# RL6845_IP_SVD register map
Vendor: Realtek
Registers are 32-bit, read-write, reset 0x0 unless marked. A register's access mark holds for its fields unless they carry their own. Offsets are from the block's base; [hi:lo] are bit positions; {n}, {i} and the like mark numbered series; <NAME> marks a mode.

## page5
Base 0x40000000
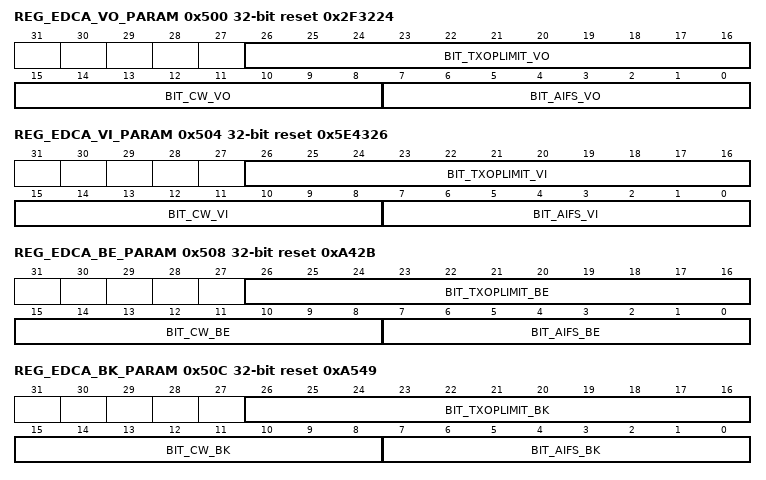
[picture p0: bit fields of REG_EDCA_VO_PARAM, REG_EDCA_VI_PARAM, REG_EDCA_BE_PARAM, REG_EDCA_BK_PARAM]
0x500 REG_EDCA_VO_PARAM reset 0x2F3224
  [26:16] BIT_TXOPLIMIT_VO — TXOP Limit An unsigned integer in units of 32 microseconds. Value of zero indicates that a single MSDU or MMPDU in addition to a protection frame exchange can be transmitted at any rate. Default: BK = 0h; BE = 0h; VI = 5Eh; VO = 2Fh.
  [15:8] BIT_CW_VO — ECWmin and ECWmax encode the values of Cwmin and Cwmax respectively in an exponent form. Ex: Cwmax = 2^(ECWmax)-1 Default: BK = Ah/5h; BE = Ah/5h; VI = 5h/4h; VO = 4h/3h.
  [7:0] BIT_AIFS_VO — Arbitrary Inter frame space In unit of microsecond. AIFS indicates the time a non-AP QSTA should defer before either invoking a backoff or starting a transmission Default: BK = 49h; BE = 25h; VI = 1Ch; VO = 1Ch.
0x504 REG_EDCA_VI_PARAM reset 0x5E4326
  [26:16] BIT_TXOPLIMIT_VI — TXOP Limit An unsigned integer in units of 32 microseconds. Value of zero indicates that a single MSDU or MMPDU in addition to a protection frame exchange can be transmitted at any rate. Default: BK = 0h; BE = 0h; VI = 5Eh; VO = 2Fh.
  [15:8] BIT_CW_VI — ECWmin and ECWmax encode the values of Cwmin and Cwmax respectively in an exponent form. Ex: Cwmax = 2^(ECWmax)-1 Default: BK = Ah/5h; BE = Ah/5h; VI = 5h/4h; VO = 4h/3h.
  [7:0] BIT_AIFS_VI — Arbitrary Inter frame space In unit of microsecond. AIFS indicates the time a non-AP QSTA should defer before either invoking a backoff or starting a transmission Default: BK = 49h; BE = 25h; VI = 1Ch; VO = 1Ch.
0x508 REG_EDCA_BE_PARAM reset 0xA42B
  [26:16] BIT_TXOPLIMIT_BE — TXOP Limit An unsigned integer in units of 32 microseconds. Value of zero indicates that a single MSDU or MMPDU in addition to a protection frame exchange can be transmitted at any rate. Default: BK = 0h; BE = 0h; VI = 5Eh; VO = 2Fh.
  [15:8] BIT_CW_BE — ECWmin and ECWmax encode the values of Cwmin and Cwmax respectively in an exponent form. Ex: Cwmax = 2^(ECWmax)-1 Default: BK = Ah/5h; BE = Ah/5h; VI = 5h/4h; VO = 4h/3h.
  [7:0] BIT_AIFS_BE — Arbitrary Inter frame space In unit of microsecond. AIFS indicates the time a non-AP QSTA should defer before either invoking a backoff or starting a transmission Default: BK = 49h; BE = 25h; VI = 1Ch; VO = 1Ch.
0x50C REG_EDCA_BK_PARAM reset 0xA549
  [26:16] BIT_TXOPLIMIT_BK — TXOP Limit An unsigned integer in units of 32 microseconds. Value of zero indicates that a single MSDU or MMPDU in addition to a protection frame exchange can be transmitted at any rate. Default: BK = 0h; BE = 0h; VI = 5Eh; VO = 2Fh.
  [15:8] BIT_CW_BK — ECWmin and ECWmax encode the values of Cwmin and Cwmax respectively in an exponent form. Ex: Cwmax = 2^(ECWmax)-1 Default: BK = Ah/5h; BE = Ah/5h; VI = 5h/4h; VO = 4h/3h.
  [7:0] BIT_AIFS_BK — Arbitrary Inter frame space In unit of microsecond. AIFS indicates the time a non-AP QSTA should defer before either invoking a backoff or starting a transmission Default: BK = 49h; BE = 25h; VI = 1Ch; VO = 1Ch.
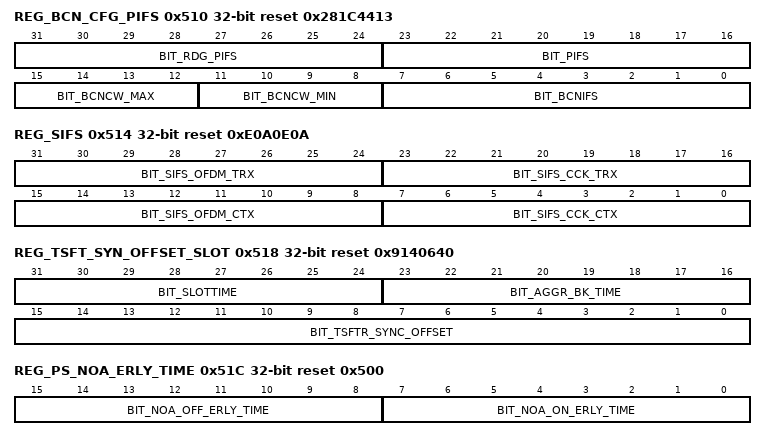
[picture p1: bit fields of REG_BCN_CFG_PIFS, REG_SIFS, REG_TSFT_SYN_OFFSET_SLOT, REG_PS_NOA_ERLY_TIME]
0x510 REG_BCN_CFG_PIFS reset 0x281C4413
  [31:24] BIT_RDG_PIFS — PIFS time. It is only used in RDG mode and in units of us.
  [23:16] BIT_PIFS — PIFS time. It is only used in AP mode and in units of us.
  [15:12] BIT_BCNCW_MAX — Beacon Contention Window MAX Defines the contention window value for back off before transmitting beacon frame. This field is set to 0 in AP mode to indicate no back off window. In ad hoc mode, its default value is 6. 26-1 = 63 time slots.
  [11:8] BIT_BCNCW_MIN — Beacon Contention Window Defines the contention window value for back off before transmitting beacon frame. This field is set to 0 in AP mode to indicate no back off window. In ad hoc mode, its default value is 6. 26-1 = 63 time slots.
  [7:0] BIT_BCNIFS — Beacon Interframe Space In units of microseconds, this register defines the medium idle time required before transmitting beacon (AP mode) or entering random back off window.
0x514 REG_SIFS reset 0xE0A0E0A
  [31:24] BIT_SIFS_OFDM_TRX — This register sets the SIFS time required in NAV protection period after receiving any immediate response. for example Ack-Data or RTS/CTS-Data. It is in unit of us.
  [23:16] BIT_SIFS_CCK_TRX — This register sets the SIFS time required in NAV protection period after receiving any immediate response. for example Ack-Data or RTS/CTS-Data. It is in unit of us.
  [15:8] BIT_SIFS_OFDM_CTX — This register sets the SIFS time required for consecutive TX events for example CTS2S-Data, or broadcast bursting. It is in unit of us.
  [7:0] BIT_SIFS_CCK_CTX — This register sets the SIFS time required for consecutive TX events for example CTS2S-Data, or broadcast bursting. It is in unit of us.
0x518 REG_TSFT_SYN_OFFSET_SLOT reset 0x9140640
  [31:24] BIT_SLOTTIME — This register sets the slot time value mentioned in 802.11 specification. It is in units of us. Default: 0x9
  [23:16] BIT_AGGR_BK_TIME — Hw will break aggr. In sifs condition
  [15:0] BIT_TSFTR_SYNC_OFFSET — tsft sync. Offset (bcn0 sync to bcn1 offset or bcn1 sync to bcn0 offset). Unit : 32us, default is 50ms
0x51C REG_PS_NOA_ERLY_TIME reset 0x500
  [15:8] BIT_NOA_OFF_ERLY_TIME — NOA off early interval, Time unit is TU.
  [7:0] BIT_NOA_ON_ERLY_TIME — not valid. NOA on early interval, Time unit is TU. PS: This function has some issue, so it's value must be 0
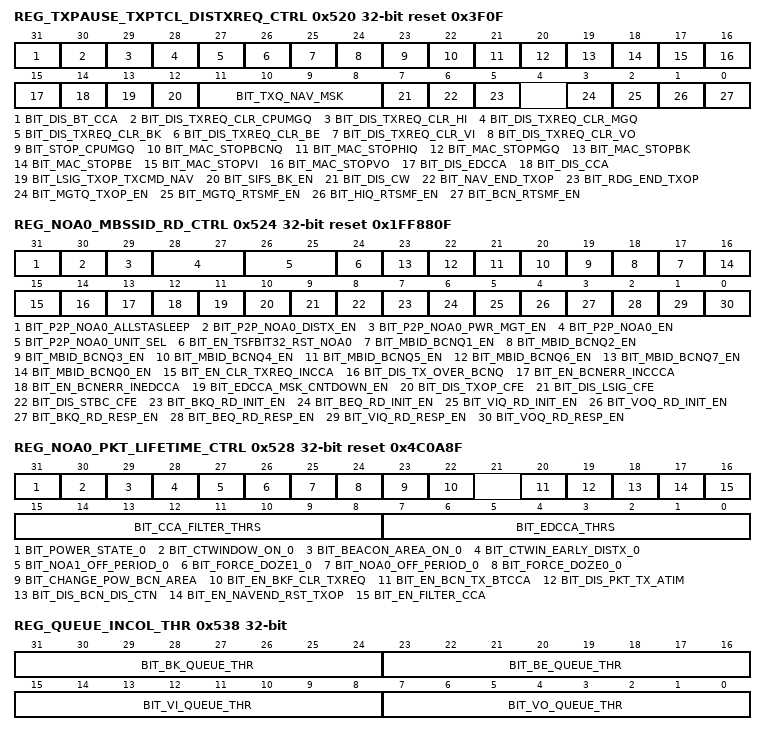
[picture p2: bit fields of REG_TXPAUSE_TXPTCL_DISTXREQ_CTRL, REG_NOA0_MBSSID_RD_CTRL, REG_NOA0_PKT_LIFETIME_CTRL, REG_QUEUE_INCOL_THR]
0x520 REG_TXPAUSE_TXPTCL_DISTXREQ_CTRL reset 0x3F0F
  [31] BIT_DIS_BT_CCA — Disable BT_CCA.
  [30] BIT_DIS_TXREQ_CLR_CPUMGQ — 1: if this queue can't own channel ,txcmd will be cleared 0:Only TX_finish can clear txreq
  [29] BIT_DIS_TXREQ_CLR_HI — 0: if this queue can't own channel ,txcmd will be cleared 1:Only TX_finish can clear txreq
  [28] BIT_DIS_TXREQ_CLR_MGQ — 1: if this queue can't own channel ,txcmd will be cleared 0:Only TX_finish can clear txreq
  [27] BIT_DIS_TXREQ_CLR_BK — 0: if this queue can't own channel ,txcmd will be cleared 1:Only TX_finish can clear txreq
  [26] BIT_DIS_TXREQ_CLR_BE — 0: if this queue can't own channel ,txcmd will be cleared 1:Only TX_finish can clear txreq
  [25] BIT_DIS_TXREQ_CLR_VI — 0: if this queue can't own channel ,txcmd will be cleared 1:Only TX_finish can clear txreq
  [24] BIT_DIS_TXREQ_CLR_VO — 0: if this queue can't own channel ,txcmd will be cleared 1:Only TX_finish can clear txreq
  [23] BIT_STOP_CPUMGQ — To control CPUMGQ queues contention circuit. 1: CPUMGQ queues all stop. 0: Enable CPUMGQ queues contention circuit
  [22] BIT_MAC_STOPBCNQ — Stop BCNQ Queue Write a 1 to this bit via software to immediately stop the transmission of packet from this queue including retry attempts.
  [21] BIT_MAC_STOPHIQ — Stop High Queue Write a 1 to this bit via software to immediately stop the transmission of packet from this queue including retry attempts.
  [20] BIT_MAC_STOPMGQ — Stop Management Queue Write a 1 to this bit via software to immediately stop the transmission of packet from this queue including retry attempts.
  [19] BIT_MAC_STOPBK — Stop BK Queue Write a 1 to this bit via software to immediately stop the transmission of packet from this queue including retry attempts.
  [18] BIT_MAC_STOPBE — Stop BE Queue Write a 1 to this bit via software to immediately stop the transmission of packet from this queue including retry attempts.
  [17] BIT_MAC_STOPVI — Stop VI Queue Write a 1 to this bit via software to immediately stop the transmission of packet from this queue including retry attempts.
  [16] BIT_MAC_STOPVO — Stop VO Queue Write a 1 to this bit via software to immediately stop the transmission of packet from this queue including retry attempts.
  [15] BIT_DIS_EDCCA — Disable EDCCA function. 0: PHY_EDCCA can block TX (default) 1: PHY_EDCCA cannot block TX OK -> TX beacon; X -> cannot TX beacon 0x528[7] 0x520[15] 0x520[14] TX bcn TX bcn (OFDMCCA=0, (OFDMCCA=1, EDCCA=1) EDCCA=1) 0 0 0 X X 0 0 1 X X 0 1 0 OK X 0 1 1 OK OK 1 0 0 X X 1 0 1 X X 1 1 0 OK X 1 1 1 OK OK
  [14] BIT_DIS_CCA — Disable CCA.
  [13] BIT_LSIG_TXOP_TXCMD_NAV — Set LSIG_TXOP from TXCMD_NAV field
  [12] BIT_SIFS_BK_EN — SIFS Break Check Criteria enable for AMPDU aggregation
  [11:8] BIT_TXQ_NAV_MSK — 1: Queue BKF must wait TX Nav finished 0: Queue not need wait
  [7] BIT_DIS_CW — When this bit is set, disable CW.
  [6] BIT_NAV_END_TXOP — 1: In txop mode, Nav protect all txop 0: In txop mode, Nav protect to next pkt
  [5] BIT_RDG_END_TXOP — 1: In tx RDG mode, Nav protect all txop 0: In tx RDG mode, Nav protect to next pkt
  [3] BIT_MGTQ_TXOP_EN — When this bit is set, MGTQ may sent packets by using ACQ TXOP.
  [2] BIT_MGTQ_RTSMF_EN — When this bit is set, MTGQ will be TX, not wait until RTS or MF transaction finished.
  [1] BIT_HIQ_RTSMF_EN — When this bit is set, HIQ will be TX, not wait until RTS or MF transaction finished.
  [0] BIT_BCN_RTSMF_EN — When this bit is set, BCNQ will be TX, not wait until RTS or MF transaction finished.
0x524 REG_NOA0_MBSSID_RD_CTRL reset 0x1FF880F
  [31] BIT_P2P_NOA0_ALLSTASLEEP — It indicates that the state from CTWindow End to BcnEarly 1: Sleep 0: Wake
  [30] BIT_P2P_NOA0_DISTX_EN — 1: Hw will disable TX in P2P_off period 0: Do Nothing
  [29] BIT_P2P_NOA0_PWR_MGT_EN — A main switch for P2P PowerSaving 1: Enable 0: Disable
  [28:27] BIT_P2P_NOA0_EN — The condition that noa_unit0, [1]-NOA1, [0]-NOA0 1: Enable 0: Disable
  [26:25] BIT_P2P_NOA0_UNIT_SEL — The selector for the source of noa unit0. 0 for port 0, 1 for port 1,2 for port2
  [24] BIT_EN_TSFBIT32_RST_NOA0 — when enable, if tsft_bit32_int is asserted, reset power_cs of noa_unit0
  [n+16] BIT_MBID_BCNQ{n}_EN (n=1..7) — When enable, auto MBSSID for virtual interface {n} is enable.
  [16] BIT_MBID_BCNQ0_EN — When enable, auto MBSSID for root interface is enable.
  [15] BIT_EN_CLR_TXREQ_INCCA — not valid.
  [14] BIT_DIS_TX_OVER_BCNQ — 1: Tx Packet with ignoring Beacon Area time 0: Disable
  [13] BIT_EN_BCNERR_INCCCA — eneble force tx becon ignore CCA in disable contention area
  [12] BIT_EN_BCNERR_INEDCCA — eneble force tx becon ignore EDCCA in disable contention area
  [11] BIT_EDCCA_MSK_CNTDOWN_EN — 1: disable EDCCA count down, 0: enable EDCCA count down AC backoff 是否需要參考PHY_EDCCA 0: 不參考PHY_EDCCA 1: 參考PHY_EDCCA (default, PHY_EDCCA=1時停止backoff)
  [10] BIT_DIS_TXOP_CFE — Disable TXOP_CFE function
  [9] BIT_DIS_LSIG_CFE — Disable LSIG_TXOP CF-END function
  [8] BIT_DIS_STBC_CFE — Disable STBC CF-END function
  [7] BIT_BKQ_RD_INIT_EN — Enable BKQ RD initiator function
  [6] BIT_BEQ_RD_INIT_EN — Enable BEQ RD initiator function
  [5] BIT_VIQ_RD_INIT_EN — Enable VIQ RD initiator function
  [4] BIT_VOQ_RD_INIT_EN — Enable VOQ RD initiator function
  [3] BIT_BKQ_RD_RESP_EN — Enable BKQ RD responder function
  [2] BIT_BEQ_RD_RESP_EN — Enable BEQ RD responder function
  [1] BIT_VIQ_RD_RESP_EN — Enable VIQ RD responder function
  [0] BIT_VOQ_RD_RESP_EN — Enable VOQ RD responder function
0x528 REG_NOA0_PKT_LIFETIME_CTRL access per field reset 0x4C0A8F
  [31] BIT_POWER_STATE_0 ro — 1: On, 0: Off. (It is including early time. )
  [30] BIT_CTWINDOW_ON_0 ro — Spec time and Beacon Early Time to TBTT Time. (It is including early time. )
  [29] BIT_BEACON_AREA_ON_0 ro — The time is from HOLD Time to BeaconTx or Timeout. (It is including early time. )
  [28] BIT_CTWIN_EARLY_DISTX_0 ro — ctwin_early_distx. (It is including early time. )
  [27] BIT_NOA1_OFF_PERIOD_0 ro — Spec time but exclude BCNDMATIM time for wake. (It is including early time. )
  [26] BIT_FORCE_DOZE1_0 ro — If NoA_Count == 1, this value is 1. else 0. (It is including early time. )
  [25] BIT_NOA0_OFF_PERIOD_0 ro — Spec time but exclude BCNDMATIM time for wake. (It is including early time. )
  [24] BIT_FORCE_DOZE0_0 ro — If NoA_Count == 1, this value is 1. else 0. (It is including early time. )
  [23] BIT_CHANGE_POW_BCN_AREA rw — select real_ctwindow & real_bcnq_area for noa_unit
  [22] BIT_EN_BKF_CLR_TXREQ rw — when gen tx command done, while will backoff is invalid, then tx command will be cleared
  [20] BIT_EN_BCN_TX_BTCCA rw — 1: Enable Beacon Tx at TBTT if BT_CCA is enabled 0: Disable
  [19] BIT_DIS_PKT_TX_ATIM rw — 1: Disable AC Queue Packet Tx in ATIM (only valid at Nettype: Adhoc/AP) 0: Enable AC Queue packet Tx in ATIM
  [18] BIT_DIS_BCN_DIS_CTN rw — Disable the Beacon queue disable contention,when set to 0 enable the force beacon function.
  [17] BIT_EN_NAVEND_RST_TXOP rw — When set this bit, TXOP will be reset while NAV end.
  [16] BIT_EN_FILTER_CCA rw — Enable CCA filter threshold
  [15:8] BIT_CCA_FILTER_THRS rw — If PHY_CCA signal width is bigger than this threshold, this PHY_CCA signal is valid for MAC. Unit: us
  [7:0] BIT_EDCCA_THRS rw — EDCCA threshold value, edcca over this threshold will cause bkf_rst Bit[7]: PHY_EDCCA為1時,當timer timeout時擋住TX Bit[6:0]: timer (單位:32us)
0x530 REG_P2PON_DIS_TXTIME
  [15:8] BIT_P2PON_DIS_TXTIME — The time of the disable TX period after the P2P RF on interrupt occur. Unit: 64us.
0x534 REG_NAN_SETTING_2 reset 0x168
  [13:0] BIT_SYNC_BCN_DELAY — r_HC * r_SLOTTIME * 8'd40 (unit:us) default: r_HC = 1, r_SLOTTIME = 9, => 360us max is 16ms (DW)
0x538 REG_QUEUE_INCOL_THR
  [31:24] BIT_BK_QUEUE_THR — 0: Disable this BK queue condition. Otherwise: When internal collision number of queue equal threshold, the priority of queue enhance. But have more 2 queues which satisfy each queue threshold, the priority will follow VO>VI>BE>BK.
  [23:16] BIT_BE_QUEUE_THR — 0: Disable this BE queue condition. Otherwise: When internal collision number of queue equal threshold, the priority of queue enhance. But have more 2 queues which satisfy each queue threshold, the priority will follow VO>VI>BE>BK.
  [15:8] BIT_VI_QUEUE_THR — 0: Disable this VI queue condition. Otherwise: When internal collision number of queue equal threshold, the priority of queue enhance. But have more 2 queues which satisfy each queue threshold, the priority will follow VO>VI>BE>BK.
  [7:0] BIT_VO_QUEUE_THR — 0: Disable this VO queue condition. Otherwise: When internal collision number of queue equal threshold, the priority of queue enhance. But have more 2 queues which satisfy each queue threshold, the priority will follow VO>VI>BE>BK.
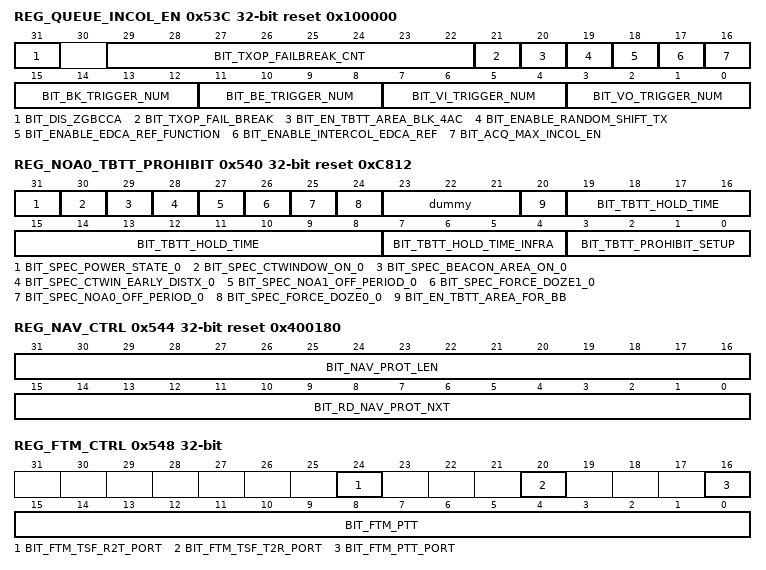
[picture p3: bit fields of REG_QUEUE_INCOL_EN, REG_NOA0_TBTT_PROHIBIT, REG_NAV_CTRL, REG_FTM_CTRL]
0x53C REG_QUEUE_INCOL_EN access per field reset 0x100000
  [31] BIT_DIS_ZGBCCA rw — Disable zigbee CCA
  [29:22] BIT_TXOP_FAILBREAK_CNT ro — if BIT_TXOP_FAIL_BREAK = 1, counter the times of txfail break TXOP
  [21] BIT_TXOP_FAIL_BREAK rw — 1: if tx pkt fail in txop, then tx cfend to end txop
  [20] BIT_EN_TBTT_AREA_BLK_4AC rw — When set this bit, 4AC backoff is disabled on TBTT setup period
  [19] BIT_ENABLE_RANDOM_SHIFT_TX rw — When this bit set 1, enable random shift TX function
  [18] BIT_ENABLE_EDCA_REF_FUNCTION rw — When this bit set 1, enable EDCA REF function
  [17] BIT_ENABLE_INTERCOL_EDCA_REF rw — When this bit set 1, enable inter-collision edca_ref
  [16] BIT_ACQ_MAX_INCOL_EN rw — 1:Enable 0 :Disable
  [15:12] BIT_BK_TRIGGER_NUM ro — The number is triggered by bkq inter collision
  [11:8] BIT_BE_TRIGGER_NUM ro — The number is triggered by beq inter collision
  [7:4] BIT_VI_TRIGGER_NUM ro — The number is triggered by viq inter collision
  [3:0] BIT_VO_TRIGGER_NUM ro — The number is triggered by voq inter collision
0x540 REG_NOA0_TBTT_PROHIBIT access per field reset 0xC812
  [31] BIT_SPEC_POWER_STATE_0 ro — 1: On, 0: Off
  [30] BIT_SPEC_CTWINDOW_ON_0 ro — The time from TBTT <-> CTWEND (with BCNDMATIM early time)
  [29] BIT_SPEC_BEACON_AREA_ON_0 ro — The time is from TBTT to BeaconTx or Timeout
  [28] BIT_SPEC_CTWIN_EARLY_DISTX_0 ro — ctwin_early_distx
  [27] BIT_SPEC_NOA1_OFF_PERIOD_0 ro — Spec time
  [26] BIT_SPEC_FORCE_DOZE1_0 ro — If NoA_Count == 1, this value is 1. else 0.
  [25] BIT_SPEC_NOA0_OFF_PERIOD_0 ro — Spec time
  [24] BIT_SPEC_FORCE_DOZE0_0 ro — If NoA_Count == 1, this value is 1. else 0.
  [23:21] dummy rw
  [20] BIT_EN_TBTT_AREA_FOR_BB rw — enable notify bb that mac p0 is in tbtt area
  [19:8] BIT_TBTT_HOLD_TIME rw — TBTT_prohibit_hold time for AP mode, unit is 32 us
  [7:4] BIT_TBTT_HOLD_TIME_INFRA rw — TBTT_prohibit_hold time for infrastructure mode , unit is 2 ms
  [3:0] BIT_TBTT_PROHIBIT_SETUP rw — TBTT_prohibit_setup, unit is 32us
0x544 REG_NAV_CTRL reset 0x400180
  [31:16] BIT_NAV_PROT_LEN — In TXOP mode ,NAV setting which protects next packets
  [15:0] BIT_RD_NAV_PROT_NXT — In RDG mode ,NAV setting which protects next packets
0x548 REG_FTM_CTRL
  [24] BIT_FTM_TSF_R2T_PORT — 0:R2T latch count sync tsf of port 0 1: R2T latch count sync tsf of port 1
  [20] BIT_FTM_TSF_T2R_PORT — 0:T2R latch count sync tsf of port 0 1: T2R latch count sync tsf of port 1
  [16] BIT_FTM_PTT_PORT — 0: sync tsf of port 0 1: sync tsf of port 1
  [15:0] BIT_FTM_PTT — partial tsf timer setting
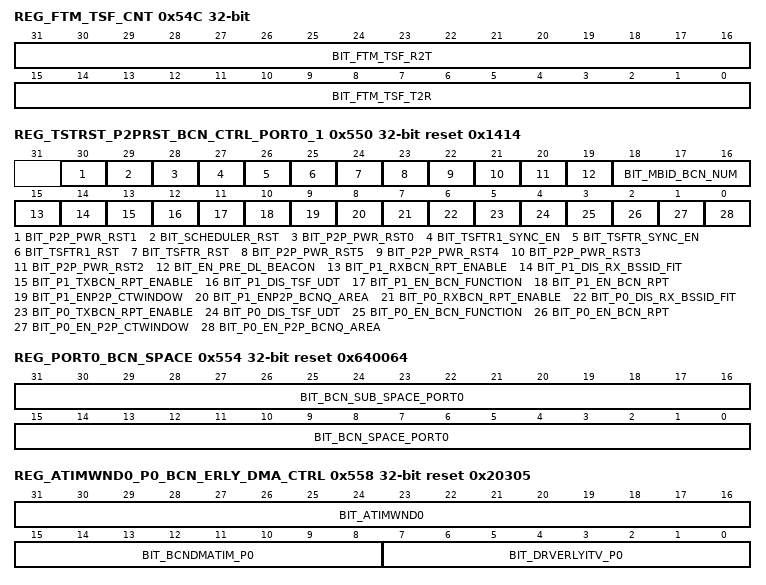
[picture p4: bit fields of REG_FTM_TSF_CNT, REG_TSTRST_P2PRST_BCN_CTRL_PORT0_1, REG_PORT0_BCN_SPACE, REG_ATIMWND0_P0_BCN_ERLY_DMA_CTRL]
0x54C REG_FTM_TSF_CNT ro
  [31:16] BIT_FTM_TSF_R2T — R2T latch count sync tsf timer
  [15:0] BIT_FTM_TSF_T2R — T2R latch count sync tsf timer
0x550 REG_TSTRST_P2PRST_BCN_CTRL_PORT0_1 access per field reset 0x1414
  [30] BIT_P2P_PWR_RST1 wo — rst p2p circuit NOA 1, noa_unit0
  [29] BIT_SCHEDULER_RST wo — Write this bit reset scheduler, ioreg_txfail
  [28] BIT_P2P_PWR_RST0 wo — rst p2p circuit NOA 0, noa_unit0
  [27] BIT_TSFTR1_SYNC_EN wo — write this bit, bcn1 will sync to bcn0 with TSFTF_SYN_OFFSET
  [26] BIT_TSFTR_SYNC_EN wo — write this bit, bcn0 will sync to bcn1 with TSFTF_SYN_OFFSET
  [25] BIT_TSFTR1_RST wo — write this bit , bcn1 tsft will auto reset
  [24] BIT_TSFTR_RST wo — write this bit , bcn0 tsft will auto reset
  [23] BIT_P2P_PWR_RST5 wo — rst p2p circuit NOA 5, noa_unit2
  [22] BIT_P2P_PWR_RST4 wo — rst p2p circuit NOA 4, noa_unit2
  [21] BIT_P2P_PWR_RST3 wo — rst p2p circuit NOA 3, noa_unit1
  [20] BIT_P2P_PWR_RST2 wo — rst p2p circuit NOA 2, noa_unit1
  [19] BIT_EN_PRE_DL_BEACON rw — If set 1, hw will enable pre_download beacon
  [18:16] BIT_MBID_BCN_NUM rw — The number of virtual interface number excluding the root number.
  [15] BIT_P1_RXBCN_RPT_ENABLE rw — When this bit asserted, RXBCNOK report is issued
  [14] BIT_P1_DIS_RX_BSSID_FIT rw — 0:HW will handle rx_beacon 1:HW will ignore rx_beacon_pk
  [13] BIT_P1_TXBCN_RPT_ENABLE rw — When this bit and BIT_P1_EN_BCN_RPT are set, then TXBCN ERROR report is issued
  [12] BIT_P1_DIS_TSF_UDT rw — When set, disable clint 0 TSF update when beacon frames or probe response frames are received.
  [11] BIT_P1_EN_BCN_FUNCTION rw — When this bit is set, TSF and other beacon related functions are then enabled. 0x700(MACID1)的enable開關
  [10] BIT_P1_EN_BCN_RPT rw — When this bit asserted, txbcnok_int and txbcnerr_int will valid.
  [9] BIT_P1_ENP2P_CTWINDOW rw — 1: Enable P2P CTN WINDOWS function. 0: Disable P2P CTN WINDOWS function.
  [8] BIT_P1_ENP2P_BCNQ_AREA rw — 1: Enable P2P BCN area on function. 0 : Disable P2P BCN area on function.
  [7] BIT_P0_RXBCN_RPT_ENABLE rw — When this bit asserted, RXBCNOK report is issued
  [6] BIT_P0_DIS_RX_BSSID_FIT rw — 0:HW will handle rx_beacon 1:HW will ignore rx_beacon_pk
  [5] BIT_P0_TXBCN_RPT_ENABLE rw — When this bit and BIT_P0_EN_BCN_RPT are set, then TXBCN ERROR report is issued
  [4] BIT_P0_DIS_TSF_UDT rw — When set, disable port 0 TSF update when beacon frames or probe response frames are received.
  [3] BIT_P0_EN_BCN_FUNCTION rw — When this bit is set, TSF and other beacon related functions are then enabled. 0x610(MACID)的enable開關
  [2] BIT_P0_EN_BCN_RPT rw — When this bit asserted, txbcnok_int and txbcnerr_int will valid.
  [1] BIT_P0_EN_P2P_CTWINDOW rw — 1: Enable P2P CTN WINDOWS function. 0: Disable P2P CTN WINDOWS function.
  [0] BIT_P0_EN_P2P_BCNQ_AREA rw — 1: Enable P2P BCN area on function. 0 : Disable P2P BCN area on function.
0x554 REG_PORT0_BCN_SPACE reset 0x640064
  [31:16] BIT_BCN_SUB_SPACE_PORT0 — Unit is ms. The sub-beacon interval of the port 0.(valid if mbssid function is enable)
  [15:0] BIT_BCN_SPACE_PORT0 — Unit is ms. When MBSSID is disable, this field is the beacon interval. When MBSSID is enable, this register is the beacon space of root.
0x558 REG_ATIMWND0_P0_BCN_ERLY_DMA_CTRL reset 0x20305
  [31:16] BIT_ATIMWND0 — ATIM window width of root VAP in units of TU.
  [15:8] BIT_BCNDMATIM_P0 — Indicates the time before TBTT to perform beacon queue DMA. This register is shared by the time to assert ATIM window end interrupt. Measured in units of "TU" before TBTT and before ATIM window end.
  [7:0] BIT_DRVERLYITV_P0 — Time to send interrupt to notify driver to change beacon content. Time unit is TU. The register also is shared by P2P-CTW and P2P-NoA (from NoA-Absent to NoA-On). It is used to wake up early at DriverEarlyTime
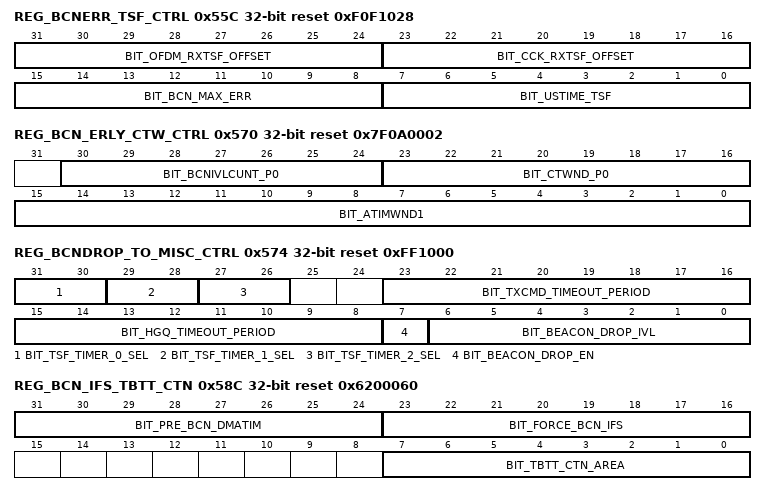
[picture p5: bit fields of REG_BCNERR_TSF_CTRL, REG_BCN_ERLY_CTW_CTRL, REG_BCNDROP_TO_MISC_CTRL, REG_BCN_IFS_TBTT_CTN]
0x55C REG_BCNERR_TSF_CTRL reset 0xF0F1028
  [31:24] BIT_OFDM_RXTSF_OFFSET — The Datapath of OFDM RX_tsf
  [23:16] BIT_CCK_RXTSF_OFFSET — The Datapath of CCK RX_tsf
  [15:8] BIT_BCN_MAX_ERR — When beacon TX error counter goes over this threshold, Beacon will transmit within PIFS.
  [7:0] BIT_USTIME_TSF — Set the microsecond time unit used by MAC TSF clock. 0x14 - 20MHz 0x28 - 40MHz 0x50 - 80MHz
0x560 REG_P0_TSFTR_L reset 0x1
  [31:0] BIT_P0_TSF_TIMER_L — low 32bits of port0's tsft
0x564 REG_P0_TSFTR_H
  [31:0] BIT_P0_TSF_TIMER_H — high 32bits of port0's tsft
0x568 REG_P1_TSFTR_L reset 0x1
  [31:0] BIT_P1_TSF_TIMER_L — low 32bits of port1's tsft
0x56C REG_P1_TSFTR_H reset 0x1
  [31:0] BIT_P1_TSF_TIMER_H — high 32bits of port1's tsft
0x570 REG_BCN_ERLY_CTW_CTRL access per field reset 0x7F0A0002
  [30:24] BIT_BCNIVLCUNT_P0 ro — Be used in multiple BCNIVL early INT. When this counter =1, multiple BCNIVL early INT will be triggered.
  [23:16] BIT_CTWND_P0 rw — CTWindow width in units of TU. PORT0
  [15:0] BIT_ATIMWND1 rw — ATIM window width of VAP1 in units of TU.
0x574 REG_BCNDROP_TO_MISC_CTRL reset 0xFF1000
  [31:30] BIT_TSF_TIMER_0_SEL — genarete tsfime_int[0] 00: PORT0's tsft 01: PORT1's tsft 10:PORT2's tsft 11: FREERUN CUT
  [29:28] BIT_TSF_TIMER_1_SEL — genarete tsfime_int[1] 00: PORT0's tsft 01: PORT1's tsft 10:PORT2's tsft 11: FREERUN CUT
  [27:26] BIT_TSF_TIMER_2_SEL — genarete tsfime_int[2] 00: PORT0's tsft 01: PORT1's tsft 10:PORT2's tsft 11: FREERUN CUT
  [23:16] BIT_TXCMD_TIMEOUT_PERIOD — When 40M/80M TX CMD ready and secondary_CCA_20/secondary_CCA_40 set for this period, then the TX CMD will be cleared. TU: 1us
  [15:8] BIT_HGQ_TIMEOUT_PERIOD — When hgq empty for this period, close atim window. And this will block hgq dma for pcie, unless 0x524[12] set enable. TU: 32us
  [7] BIT_BEACON_DROP_EN — enable beacon drop function
  [6:0] BIT_BEACON_DROP_IVL — indicate the timeout of beacon drop
0x578 REG_P2_TSFTR_L reset 0x1
  [31:0] BIT_P2_TSF_TIMER_L — low 32bits of port2's tsft
0x57C REG_P2_TSFTR_H reset 0x1
  [31:0] BIT_P2_TSF_TIMER_H — high 32bits of port2's tsft
{0x57C+4i} REG_TSF_TIMER{i} (i=1..3)
  [31:5] BIT_TSTTIMER{i} — When the lower 4 bytes of TSFTR matches the content of this register, the FW tsftime_int[{i-1}] interrupt is issued.
0x58C REG_BCN_IFS_TBTT_CTN reset 0x6200060
  [31:24] BIT_PRE_BCN_DMATIM — when 0x552[3] is set, hw will enable pre_download beacon. this register Indicates the time before TBTT to perform beacon queue DMA.
  [23:16] BIT_FORCE_BCN_IFS — when 0x528 Bit18 set to 0 and TBTT contention area end,force tx beacon use this IFS
  [7:0] BIT_TBTT_CTN_AREA — TBTT contention area,Time unit is 32us,for PORT 0 / 1 / 2
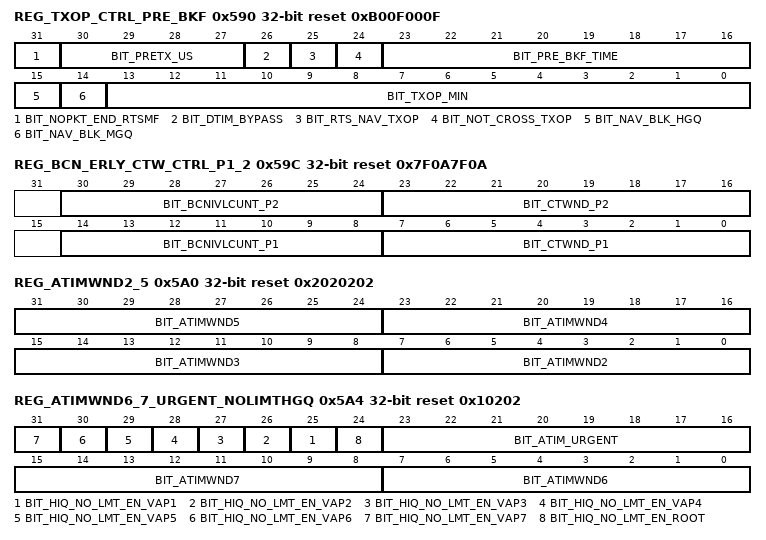
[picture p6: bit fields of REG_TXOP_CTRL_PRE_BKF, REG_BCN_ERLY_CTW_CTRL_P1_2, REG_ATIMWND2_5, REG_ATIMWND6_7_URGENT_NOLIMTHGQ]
0x590 REG_TXOP_CTRL_PRE_BKF reset 0xB00F000F
  [31] BIT_NOPKT_END_RTSMF — 1: enable exit rts hold mode when there is no corresponding ac pkt to tx
  [30:27] BIT_PRETX_US — For wep/tkip, enable security engine earlier than mactx by this amount of time. Unit is microsecond (us)
  [26] BIT_DTIM_BYPASS — 1: dtim counter will keep 0
  [25] BIT_RTS_NAV_TXOP — enable RTS NAV protect all txop
  [24] BIT_NOT_CROSS_TXOP — 1:tx pkt cross tbtt is prohibited 0:tx pkt cross tbtt is permitted
  [23:16] BIT_PRE_BKF_TIME — when bkf timer count down this value, sel queue and gen txcmd will start
  [15] BIT_NAV_BLK_HGQ — rxnav block HGQ
  [14] BIT_NAV_BLK_MGQ — rxnav block MGQ
  [13:0] BIT_TXOP_MIN — if txop counter is more than this value, than tx pkt is considered not cross tbtt
0x594 REG_FREERUN_CNT_L reset 0x1
  [31:0] BIT_FREERUN_CNT_TIMER_L — LOW 32bits of freerun cnt
0x598 REG_FREERUN_CNT_H reset 0x1
  [31:0] BIT_FREERUN_CNT_TIMER_H — high 32bits of freerun cnt
0x59C REG_BCN_ERLY_CTW_CTRL_P1_2 access per field reset 0x7F0A7F0A
  [30:24] BIT_BCNIVLCUNT_P2 ro — Be used in multiple BCNIVL early INT. When this counter =1, multiple BCNIVL early INT will be triggered.
  [23:16] BIT_CTWND_P2 rw — CTWindow width in units of TU. PORT2
  [14:8] BIT_BCNIVLCUNT_P1 ro — Be used in multiple BCNIVL early INT. When this counter =1, multiple BCNIVL early INT will be triggered.
  [7:0] BIT_CTWND_P1 rw — CTWindow width in units of TU. PORT1
0x5A0 REG_ATIMWND2_5 reset 0x2020202
  [8n-9:8n-16] BIT_ATIMWND{n} (n=2..5) — ATIM window width of VAP{n} in units of TU.
0x5A4 REG_ATIMWND6_7_URGENT_NOLIMTHGQ reset 0x10202
  [n+24] BIT_HIQ_NO_LMT_EN_VAP{n} (n=1..7) — 1: Packet in Hi Queue Tx immediately (No constraint for ATIM Period) 0: Disable
  [24] BIT_HIQ_NO_LMT_EN_ROOT — 1: Packet in Hi Queue Tx immediately (No constraint for ATIM Period) 0: Disable
  [23:16] BIT_ATIM_URGENT — Indicates the time before ATIM Window end . When BSSID[n] (n=0~7) has HIQ packet to send, HW only DMA BSSID[n]'s HIQ packet in this interval. (unit : TU)
  [15:8] BIT_ATIMWND7 — ATIM window width of VAP7 in units of TU.
  [7:0] BIT_ATIMWND6 — ATIM window width of VAP6 in units of TU.
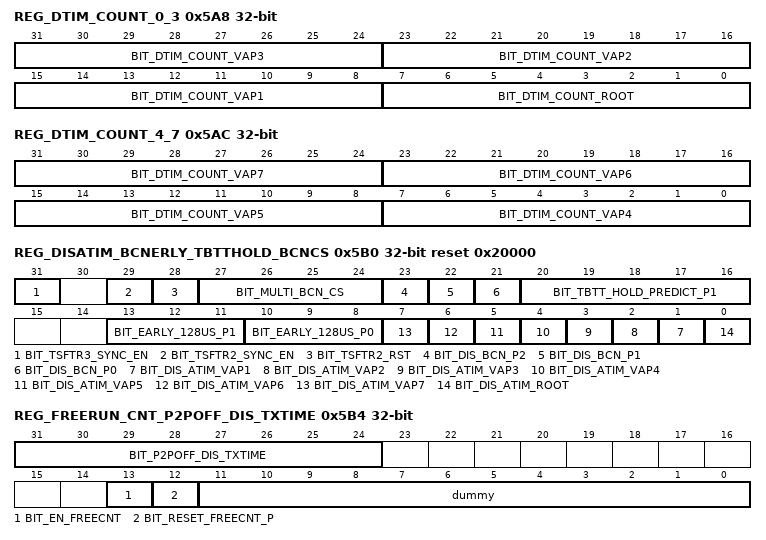
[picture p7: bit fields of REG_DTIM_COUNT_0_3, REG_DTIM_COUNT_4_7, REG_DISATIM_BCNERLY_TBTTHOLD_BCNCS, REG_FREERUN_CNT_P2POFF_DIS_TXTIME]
0x5A8 REG_DTIM_COUNT_0_3
  [31:24] BIT_DTIM_COUNT_VAP3, [23:16] BIT_DTIM_COUNT_VAP2, [15:8] BIT_DTIM_COUNT_VAP1, [7:0] BIT_DTIM_COUNT_ROOT
0x5AC REG_DTIM_COUNT_4_7
  [8n-25:8n-32] BIT_DTIM_COUNT_VAP{n} (n=4..7)
0x5B0 REG_DISATIM_BCNERLY_TBTTHOLD_BCNCS access per field reset 0x20000
  [31] BIT_TSFTR3_SYNC_EN wo — write this bit, PORT3 will sync to PORT2 with TSFTF_SYN_OFFSET
  [29] BIT_TSFTR2_SYNC_EN wo — write this bit, PORT2 will sync to PORT3 with TSFTF_SYN_OFFSET
  [28] BIT_TSFTR2_RST wo — write this bit , bcn2 tsft will auto reset
  [27:24] BIT_MULTI_BCN_CS ro — indicate which port is tx beacon
  [23] BIT_DIS_BCN_P2 rw — set 1 to mask the beacon early interrupt of port2
  [22] BIT_DIS_BCN_P1 rw — set 1 to mask the beacon early interrupt of port1
  [21] BIT_DIS_BCN_P0 rw — set 1 to mask the beacon early interrupt of port0
  [20:16] BIT_TBTT_HOLD_PREDICT_P1 rw — the predicted hold time after tbtt for beacon tx of port1, unit is 32us
  [13:11] BIT_EARLY_128US_P1 rw — the BCN EARLY interrupt find tune with unit 128us. The Total Early time of BCN early interrupt is the 0x558 x 1ms + EARLY_128us x 128us. For port 1
  [10:8] BIT_EARLY_128US_P0 rw — the BCN EARLY interrupt find tune with unit 128us. The Total Early time of BCN early interrupt is the 0x558 x 1ms + EARLY_128us x 128us.
  [n] BIT_DIS_ATIM_VAP{n} rw (n=1..7)
  [0] BIT_DIS_ATIM_ROOT rw
0x5B4 REG_FREERUN_CNT_P2POFF_DIS_TXTIME access per field
  [31:24] BIT_P2POFF_DIS_TXTIME rw — The time of the disable TX period after the P2P RF off interrupt occur. Unit: 64us.
  [13] BIT_EN_FREECNT rw — enable freerun tsft
  [12] BIT_RESET_FREECNT_P wo — reset pulse of freerun tsft
  [11:0] dummy rw
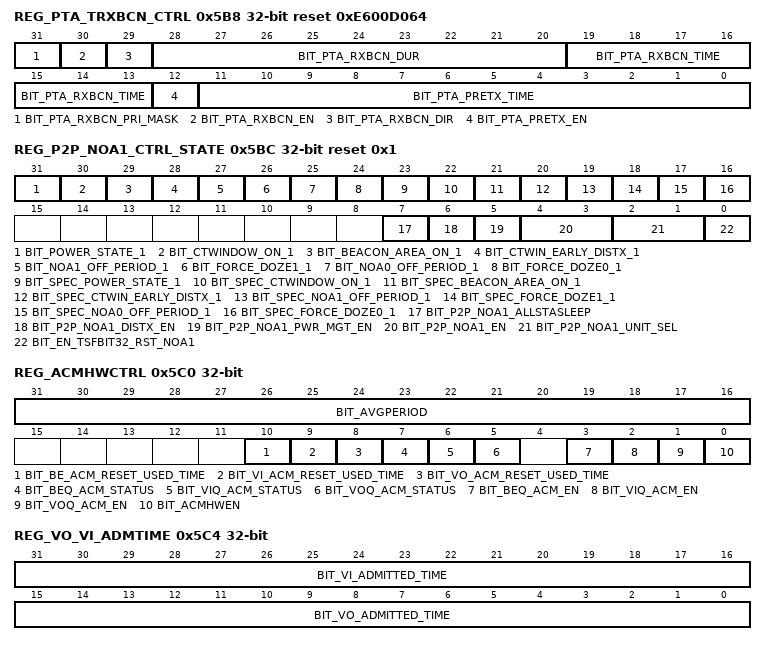
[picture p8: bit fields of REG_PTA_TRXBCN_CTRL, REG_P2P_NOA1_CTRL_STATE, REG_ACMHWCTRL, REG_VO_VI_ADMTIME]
0x5B8 REG_PTA_TRXBCN_CTRL reset 0xE600D064
  [31] BIT_PTA_RXBCN_PRI_MASK
  [30] BIT_PTA_RXBCN_EN
  [29] BIT_PTA_RXBCN_DIR
  [28:20] BIT_PTA_RXBCN_DUR
  [19:13] BIT_PTA_RXBCN_TIME
  [12] BIT_PTA_PRETX_EN
  [11:0] BIT_PTA_PRETX_TIME — WIFI TX shall wait settle time when antenna is switched from BT to WIFI, if the BT use the same RFAFE as WIFI. Unit: 1us
0x5BC REG_P2P_NOA1_CTRL_STATE access per field reset 0x1
  [31] BIT_POWER_STATE_1 ro — 1: On, 0: Off. (It is including early time. )
  [30] BIT_CTWINDOW_ON_1 ro — Spec time and Beacon Early Time to TBTT Time. (It is including early time. )
  [29] BIT_BEACON_AREA_ON_1 ro — The time is from HOLD Time to BeaconTx or Timeout. (It is including early time. )
  [28] BIT_CTWIN_EARLY_DISTX_1 ro — ctwin_early_distx. (It is including early time. )
  [27] BIT_NOA1_OFF_PERIOD_1 ro — Spec time but exclude BCNDMATIM time for wake. (It is including early time. )
  [26] BIT_FORCE_DOZE1_1 ro — If NoA_Count == 1, this value is 1. else 0. (It is including early time. )
  [25] BIT_NOA0_OFF_PERIOD_1 ro — Spec time but exclude BCNDMATIM time for wake. (It is including early time. )
  [24] BIT_FORCE_DOZE0_1 ro — If NoA_Count == 1, this value is 1. else 0. (It is including early time. )
  [23] BIT_SPEC_POWER_STATE_1 ro — 1: On, 0: Off
  [22] BIT_SPEC_CTWINDOW_ON_1 ro — The time from TBTT <-> CTWEND (with BCNDMATIM early time)
  [21] BIT_SPEC_BEACON_AREA_ON_1 ro — The time is from TBTT to BeaconTx or Timeout
  [20] BIT_SPEC_CTWIN_EARLY_DISTX_1 ro — ctwin_early_distx
  [19] BIT_SPEC_NOA1_OFF_PERIOD_1 ro — Spec time
  [18] BIT_SPEC_FORCE_DOZE1_1 ro — If NoA_Count == 1, this value is 1. else 0.
  [17] BIT_SPEC_NOA0_OFF_PERIOD_1 ro — Spec time
  [16] BIT_SPEC_FORCE_DOZE0_1 ro — If NoA_Count == 1, this value is 1. else 0.
  [7] BIT_P2P_NOA1_ALLSTASLEEP rw — It indicates that the state from CTWindow End to BcnEarly 1: Sleep 0: Wake
  [6] BIT_P2P_NOA1_DISTX_EN rw — 1: Hw will disable TX in P2P_off period 0: Do Nothing
  [5] BIT_P2P_NOA1_PWR_MGT_EN rw — A main switch for P2P PowerSaving 1: Enable 0: Disable
  [4:3] BIT_P2P_NOA1_EN rw — The condition that noa_unit0, [1]-NOA1, [0]-NOA0 1: Enable 0: Disable
  [2:1] BIT_P2P_NOA1_UNIT_SEL rw — The selector for the source of noa unit0. 0 for port 0, 1 for port 1
  [0] BIT_EN_TSFBIT32_RST_NOA1 rw
0x5C0 REG_ACMHWCTRL access per field
  [31:16] BIT_AVGPERIOD rw — In unit of 32 us. It is the value Dot11EDCAAveragingPeriod in SPEC. HW will recalculate used_time every this period. Max is 2 sec
  [10] BIT_BE_ACM_RESET_USED_TIME wo — When HwEn is enabled, software set this bit to inform hardware to reset used_time to 0. Read this bit is always 0.
  [9] BIT_VI_ACM_RESET_USED_TIME wo — When HwEn is enabled, software set this bit to inform hardware to reset used_time to 0. Read this bit is always 0.
  [8] BIT_VO_ACM_RESET_USED_TIME wo — When HwEn is enabled, software set this bit to inform hardware to reset used_time to 0. Read this bit is always 0.
  [7] BIT_BEQ_ACM_STATUS ro — This bit indicates if the used_time >= admitted_time of AC BE when HW ACM. 0: BEQ ACM Not Exceed. 1: BEQ ACM Exceed. Default: 0h
  [6] BIT_VIQ_ACM_STATUS ro — This bit indicates if the used_time >= admitted_time of AC VI when HW ACM. 0: VIQ ACM Not Exceed. 1: VIQ ACM Exceed. Default: 0h
  [5] BIT_VOQ_ACM_STATUS ro — This bit indicates if the used_time >= admitted_time of AC VO when HW ACM. 0: VOQ ACM Not Exceed. 1: VOQ ACM Exceed. Default: 0h
  [3] BIT_BEQ_ACM_EN rw — Set this bit to enable ACM of BE queue. 1: Enable 0: Disable Default: 0h
  [2] BIT_VIQ_ACM_EN rw — Set this bit to enable ACM of VI queue. 1: Enable 0: Disable Default: 0h.
  [1] BIT_VOQ_ACM_EN rw — Set this bit to enable ACM of VO queue. 1: Enable 0: Disable Default: 0h.
  [0] BIT_ACMHWEN rw — Set this bit to enable hardware to take control of ACM. 1: Hardware Control 0: Software Control Default: 0h.
0x5C4 REG_VO_VI_ADMTIME
  [31:16] BIT_VI_ADMITTED_TIME — Admitted_time of VI queue. In unit of 32 microsecond. Calculated and set by driver.
  [15:0] BIT_VO_ADMITTED_TIME — Admitted_time of VO queue. In unit of 32 microsecond. Calculated and set by driver.
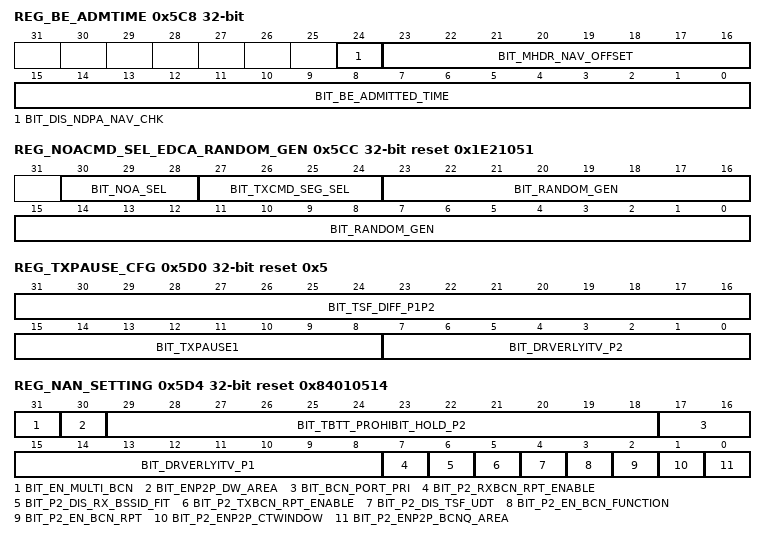
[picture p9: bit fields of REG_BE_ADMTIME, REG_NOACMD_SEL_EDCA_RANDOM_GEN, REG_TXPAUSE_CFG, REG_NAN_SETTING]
0x5C8 REG_BE_ADMTIME
  [24] BIT_DIS_NDPA_NAV_CHK — 1-->tx NDPA/NDP can cross TBTT,0-->tx NDPA/NDP can't cross TBTT
  [23:16] BIT_MHDR_NAV_OFFSET — NDPA NAV compensation value
  [15:0] BIT_BE_ADMITTED_TIME — Admitted_time of BE queue. In unit of 32 microsecond. Calculated and set by driver.
0x5CC REG_NOACMD_SEL_EDCA_RANDOM_GEN reset 0x1E21051
  [30:28] BIT_NOA_SEL — TX NoA parameter select (noa_unit0~2,parameter0~5) 0: NoA0 , 1:NoA1, 2:NoA2, 3:NoA3, 4:NoA4, default: NoA5 To control the register setting for which NOA. (register 0x05E0[103:0])
  [27:24] BIT_TXCMD_SEG_SEL — [HW Debug Info]To select which one TXCMD Segment. For example, 可以在0x5CF[3:0]填 0 or 6 讀取 0x5F8[7:0] : Tx Agg 0x5F9[7:0] : Tx Rate
  [23:0] BIT_RANDOM_GEN — Random number generator polynomial
0x5D0 REG_TXPAUSE_CFG access per field reset 0x5
  [31:16] BIT_TSF_DIFF_P1P2 ro — the difference of beacon count down value between port0 and port1, unit is TU
  [15:8] BIT_TXPAUSE1 rw — same as 0x522[7:0], allow FW/DR to control pause jointly
  [7:0] BIT_DRVERLYITV_P2 rw — Time to send interrupt to notify driver to change beacon content. Time unit is TU. It is used to wake up early at DriverEarlyTime. For port 2
0x5D4 REG_NAN_SETTING reset 0x84010514
  [31] BIT_EN_MULTI_BCN — enable multiple beacons of port0~port2
  [30] BIT_ENP2P_DW_AREA — DW condition for P2P,for port2
  [29:18] BIT_TBTT_PROHIBIT_HOLD_P2 — the predicted hold time after tbtt for beacon tx of port2, unit is 32us
  [17:16] BIT_BCN_PORT_PRI — the priority of port0 and port2. 10: port2 has higher priority than port0; 01:port0 has higher priority than port2. 00: port0 and port2 have the same priority
  [15:8] BIT_DRVERLYITV_P1 — Time to send interrupt to notify driver to change beacon content. Time unit is TU. It is used to wake up early at DriverEarlyTime. For port1
  [7] BIT_P2_RXBCN_RPT_ENABLE — When this bit asserted, RXBCNOK report is issued
  [6] BIT_P2_DIS_RX_BSSID_FIT — 0:HW will handle rx_beacon 1:HW will ignore rx_beacon_pk
  [5] BIT_P2_TXBCN_RPT_ENABLE — When this bit asserted, then TXBCN ERROR report is issued
  [4] BIT_P2_DIS_TSF_UDT — When set, disable clint 2 TSF update when beacon frames or probe response frames are received.
  [3] BIT_P2_EN_BCN_FUNCTION — When this bit is set, TSF and other beacon related functions are then enabled.
  [2] BIT_P2_EN_BCN_RPT — When this bit asserted, txbcnok_int and txbcnerr_int will valid.
  [1] BIT_P2_ENP2P_CTWINDOW — 1: Enable P2P CTN WINDOWS function. 0: Disable P2P CTN WINDOWS function.
  [0] BIT_P2_ENP2P_BCNQ_AREA — 1: Enable P2P BCN area on function. 0 : Disable P2P BCN area on function.
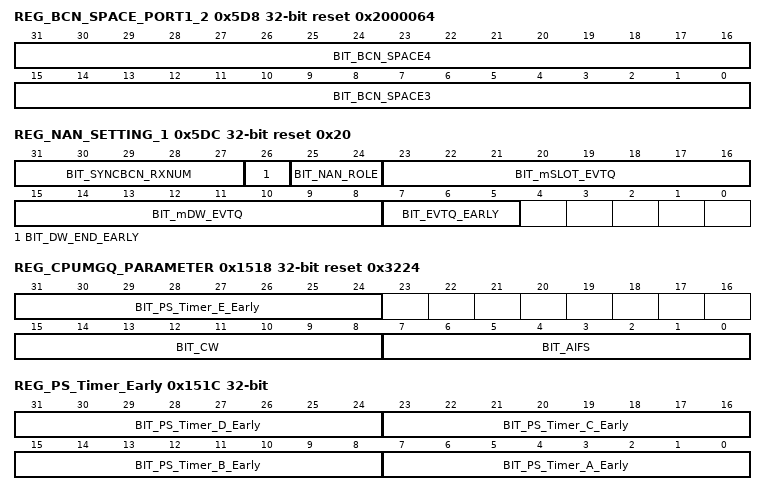
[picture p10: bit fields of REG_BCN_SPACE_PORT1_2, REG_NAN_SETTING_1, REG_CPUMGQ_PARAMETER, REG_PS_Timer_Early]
0x5D8 REG_BCN_SPACE_PORT1_2 reset 0x2000064
  [31:16] BIT_BCN_SPACE4 — sync beacon space of port2
  [15:0] BIT_BCN_SPACE3 — sync beacon space of port1
0x5DC REG_NAN_SETTING_1 reset 0x20
  [31:27] BIT_SYNCBCN_RXNUM — if DW is permitted to end early, the number of rx sync beacons is defined in this register
  [26] BIT_DW_END_EARLY — when set, the DW window end earlier than spec definition. When sync bcn and SDF had tx, and rx enough sync bcns defined by 0x5DC[31:27]. DW can early end
  [25:24] BIT_NAN_ROLE — the role of NAN device, including master, no-master sync, and no-master no-sync.
  [23:16] BIT_mSLOT_EVTQ — evtq packet will tx in the m-th SLOT of the m-th DWs
  [15:8] BIT_mDW_EVTQ — evtq packet will tx in the m-th SLOT of the m-th DWs
  [7:5] BIT_EVTQ_EARLY — the early time of evtq tx window. unit is TU
0x5E0 REG_NOA_PARAM_V1 reset 0x1000
  [31:0] BIT_NOA_DURATION_V1 — The maximum duration in units of microseconds that the P2P Group Owner shall remain absent following the start of a Notice of Absence interval.
0x5E4 REG_NOA_PARAM_V2 reset 0x3000
  [31:0] BIT_NOA_INTERVAL_V2 — The length of the Notice of Absence interval in units of microseconds.
0x5E8 REG_NOA_PARAM_V3 reset 0x1000
  [31:0] BIT_NOA_START_TIME_V3 — The start time for the schedule expressed in terms of the lower 4 bytes of the TSF timer.
0x5EC REG_NOA_PARAM_4 reset 0x3
  [7:0] BIT_NOA_COUNT_V4 — indicates the number of absence intervals
0x5F4 REG_SCHEDULER_DBG ro
  [31:0] BIT_DBG_SCHEDULER
0x5F8 REG_SCH_TXCMD ro
  [31:0] BIT_SCH_TXCMD — Scheduler TXCMD Content
0x5FC REG_PAGE5_DUMMY reset 0xFFFF0000
  [31:0] BIT_DUMMY — Dummy
0x1500 REG_PS_TIMER_A_L
  [31:0] BIT_PS_TIMER_A_L — When the TSF (that select by reg 0x1520 [25:24]) matches the content of this register, the PS_TIMER_A_INT interrupt is issued
0x1504 REG_PS_TIMER_A_H
  [31:0] BIT_PS_TIMER_A_H — When the TSF (that select by reg 0x1520 [25:24]) matches the content of this register, the PS_TIMER_A_INT interrupt is issued
0x1508 REG_PS_TIMER_B_L
  [31:0] BIT_PS_TIMER_B_L — When the TSF (that select by reg 0x1520 [29:28]) matches the content of this register, the PS_TIMER_B_INT interrupt is issued
0x150C REG_PS_TIMER_B_H
  [31:0] BIT_PS_TIMER_B_H — When the TSF(that select by reg 0x1520 [29:28]) matches the content of this register, the PS_TIMER_B_INT interrupt is issued
0x1510 REG_PS_TIMER_C_L
  [31:0] BIT_PS_TIMER_C_L — When the TSF(that select by reg 0x1520 [21:20]) matches the content of this register, the PS_TIMER_C_INT interrupt is issued
0x1514 REG_PS_TIMER_C_H
  [31:0] BIT_PS_TIMER_C_H — When the TSF(that select by reg 0x1520 [21:20]) matches the content of this register, the PS_TIMER_C_INT interrupt is issued
0x1518 REG_CPUMGQ_PARAMETER reset 0x3224
  [31:24] BIT_PS_Timer_E_Early — It is used to wake up early at PS_Timer_E_Early Time. Time unit is TU.
  [15:8] BIT_CW — ECWmin and ECWmax encode the values of Cwmin and Cwmax respectively in an exponent form. Ex: Cwmax = 2^(ECWmax)-1 Default: BK = Ah/5h; BE = Ah/5h; VI = 5h/4h; VO = 4h/3h.
  [7:0] BIT_AIFS — Arbitrary Inter frame space In unit of microsecond. AIFS indicates the time a non-AP QSTA should defer before either invoking a backoff or starting a transmission Default: BK = 49h; BE = 25h; VI = 1Ch; VO = 1Ch
0x151C REG_PS_Timer_Early
  [31:24] BIT_PS_Timer_D_Early — It is used to wake up early at PS_Timer_D_Early Time. Time unit is TU.
  [23:16] BIT_PS_Timer_C_Early — It is used to wake up early at PS_Timer_C_Early Time. Time unit is TU.
  [15:8] BIT_PS_Timer_B_Early — It is used to wake up early at PS_Timer_B_Early Time. Time unit is TU.
  [7:0] BIT_PS_Timer_A_Early — It is used to wake up early at PS_Timer_A_Early Time. Time unit is TU.
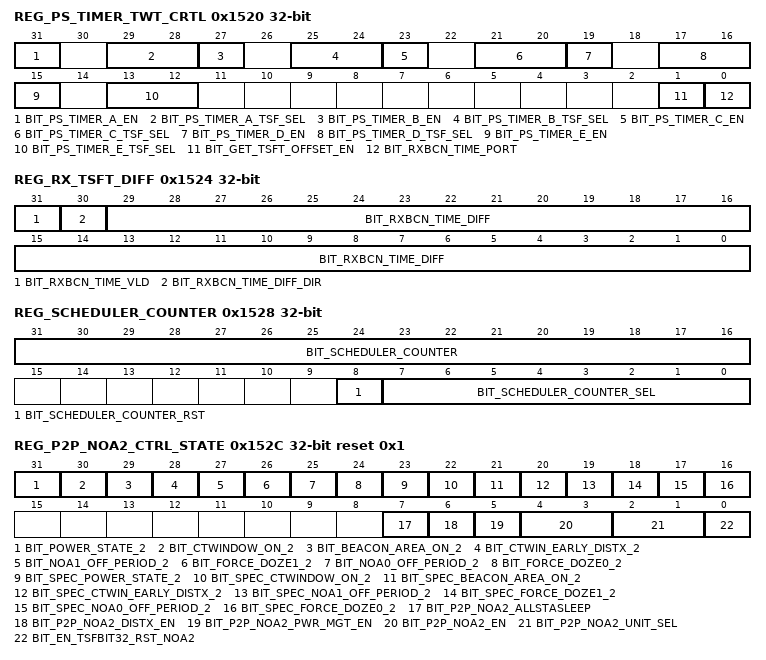
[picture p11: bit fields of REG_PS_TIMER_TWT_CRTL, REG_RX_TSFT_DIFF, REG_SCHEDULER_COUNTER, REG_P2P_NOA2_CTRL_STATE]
0x1520 REG_PS_TIMER_TWT_CRTL
  [31] BIT_PS_TIMER_A_EN — Enable PS_TIMER_B
  [29:28] BIT_PS_TIMER_A_TSF_SEL — 0 for port 0, 1 for port1, 2 for port2, 3 for freerun
  [27] BIT_PS_TIMER_B_EN — Enable PS_TIMER_A
  [25:24] BIT_PS_TIMER_B_TSF_SEL — 0 for port 0, 1 for port1, 2 for port2, 3 for freerun
  [23] BIT_PS_TIMER_C_EN — Enable PS_TIMER_C
  [21:20] BIT_PS_TIMER_C_TSF_SEL — 0 for port 0, 1 for port1, 2 for port2, 3 for freerun
  [19] BIT_PS_TIMER_D_EN — Enable PS_TIMER_D
  [17:16] BIT_PS_TIMER_D_TSF_SEL — 0 for port 0, 1 for port1, 2 for port2, 3 for freerun
  [15] BIT_PS_TIMER_E_EN — Enable PS_TIMER_E
  [13:12] BIT_PS_TIMER_E_TSF_SEL — 0 for port 0, 1 for port1, 2 for port2, 3 for freerun
  [1] BIT_GET_TSFT_OFFSET_EN — 1: Enable Enable get TSFT offset function
  [0] BIT_RXBCN_TIME_PORT — select port for report the TSFT 0: port0 1: port1 default is port0.
0x1524 REG_RX_TSFT_DIFF ro
  [31] BIT_RXBCN_TIME_VLD — 1: indicate [30:0] is valid. Write 1 to clear this bit
  [30] BIT_RXBCN_TIME_DIFF_DIR — 1: wmac_rx_tsf > TSFT 0: wmac_rx_tsf <= TSFT
  [29:0] BIT_RXBCN_TIME_DIFF — unit:1us wmac_rx_tsf - TSFT (selected by 0x1520[0]).
0x1528 REG_SCHEDULER_COUNTER access per field
  [31:16] BIT_SCHEDULER_COUNTER ro — The reported counter value corresponding to Report type selected.
  [8] BIT_SCHEDULER_COUNTER_RST rw — write "1" to set the count to zero
  [7:0] BIT_SCHEDULER_COUNTER_SEL rw — 0: No count 1: If backoff finished but CCA still assert, this counter plus one.
0x152C REG_P2P_NOA2_CTRL_STATE access per field reset 0x1
  [31] BIT_POWER_STATE_2 ro — 1: On, 0: Off. (It is including early time. )
  [30] BIT_CTWINDOW_ON_2 ro — Spec time and Beacon Early Time to TBTT Time. (It is including early time. )
  [29] BIT_BEACON_AREA_ON_2 ro — The time is from HOLD Time to BeaconTx or Timeout. (It is including early time. )
  [28] BIT_CTWIN_EARLY_DISTX_2 ro — ctwin_early_distx. (It is including early time. )
  [27] BIT_NOA1_OFF_PERIOD_2 ro — Spec time but exclude BCNDMATIM time for wake. (It is including early time. )
  [26] BIT_FORCE_DOZE1_2 ro — If NoA_Count == 1, this value is 1. else 0. (It is including early time. )
  [25] BIT_NOA0_OFF_PERIOD_2 ro — Spec time but exclude BCNDMATIM time for wake. (It is including early time. )
  [24] BIT_FORCE_DOZE0_2 ro — If NoA_Count == 1, this value is 1. else 0. (It is including early time. )
  [23] BIT_SPEC_POWER_STATE_2 ro — 1: On, 0: Off
  [22] BIT_SPEC_CTWINDOW_ON_2 ro — The time from TBTT <-> CTWEND (with BCNDMATIM early time)
  [21] BIT_SPEC_BEACON_AREA_ON_2 ro — The time is from TBTT to BeaconTx or Timeout
  [20] BIT_SPEC_CTWIN_EARLY_DISTX_2 ro — ctwin_early_distx
  [19] BIT_SPEC_NOA1_OFF_PERIOD_2 ro — Spec time
  [18] BIT_SPEC_FORCE_DOZE1_2 ro — If NoA_Count == 1, this value is 1. else 0.
  [17] BIT_SPEC_NOA0_OFF_PERIOD_2 ro — Spec time
  [16] BIT_SPEC_FORCE_DOZE0_2 ro — If NoA_Count == 1, this value is 1. else 0.
  [7] BIT_P2P_NOA2_ALLSTASLEEP rw — It indicates that the state from CTWindow End to BcnEarly 1: Sleep 0: Wake
  [6] BIT_P2P_NOA2_DISTX_EN rw — 1: Hw will disable TX in P2P_off period 0: Do Nothing
  [5] BIT_P2P_NOA2_PWR_MGT_EN rw — A main switch for P2P PowerSaving 1: Enable 0: Disable
  [4:3] BIT_P2P_NOA2_EN rw — The condition that noa_unit0, [1]-NOA1, [0]-NOA0 1: Enable 0: Disable
  [2:1] BIT_P2P_NOA2_UNIT_SEL rw — The selector for the source of noa unit0. 0 for port 0, 1 for port 1, 2 for port 2
  [0] BIT_EN_TSFBIT32_RST_NOA2 rw
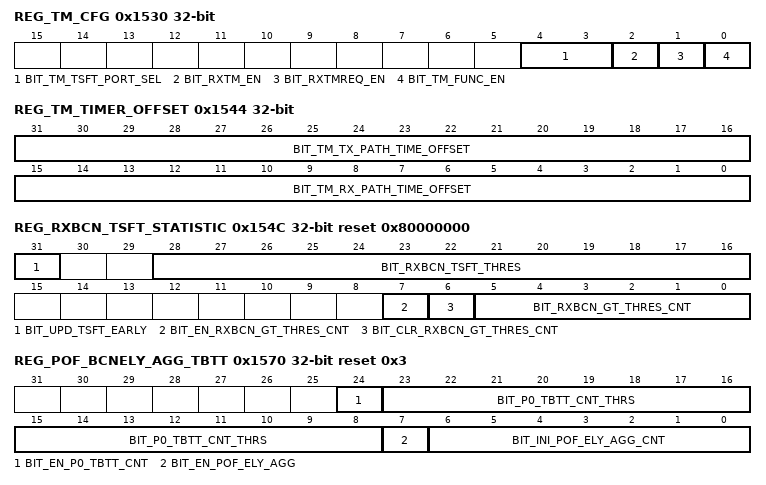
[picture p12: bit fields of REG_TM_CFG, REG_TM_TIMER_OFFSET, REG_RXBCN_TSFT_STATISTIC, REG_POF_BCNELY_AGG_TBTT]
0x1530 REG_TM_CFG
  [4:3] BIT_TM_TSFT_PORT_SEL — selected TM timer port 0: port0; 1: port1; 2: port2; 3: freerun
  [2] BIT_RXTM_EN — 1: HW will parsing rx packet, to find TM frame
  [1] BIT_RXTMREQ_EN — 1: HW will parsing rx packet, to find TM request frame
  [0] BIT_TM_FUNC_EN — 1: Enable Timing Measurement function
0x1534 REG_TM_TSFT_T1 ro
  [31:0] BIT_TM_TSFT_T1 — Latch tsft timer of Tx TM frame, unit: 1us
0x1538 REG_TM_TSFT_T2 ro
  [31:0] BIT_TM_TSFT_T2 — Latch tsft timer of Rx TM frame, unit: 1us
0x153C REG_TM_TSFT_T3 ro
  [31:0] BIT_TM_TSFT_T3 — Latch tsft timer of Tx ACK frame, unit: 1us
0x1540 REG_TM_TSFT_T4 ro
  [31:0] BIT_TM_TSFT_T4 — Latch tsft timer of Rx ACK frame, unit: 1us
0x1544 REG_TM_TIMER_OFFSET
  [31:16] BIT_TM_TX_PATH_TIME_OFFSET — Compensate the time, from PHYTXON rising edge to transmit antenna connector. unit: 1us
  [15:0] BIT_TM_RX_PATH_TIME_OFFSET — Compensate the time, from receive antenna connector to DATAON rising edge. unit: 1us
0x1548 REG_BCN_ELY_ADJ
  [15:0] BIT_BCN_ELY_ADJ — beacon early time adjust, unit is 32us
0x154C REG_RXBCN_TSFT_STATISTIC access per field reset 0x80000000
  [31] BIT_UPD_TSFT_EARLY rw — 0: don't update TSFT when the following scenarios occur: tim_no_hit, |TSFT - rxbcn.timestamp| <= BIT_RXBCN_TSFT_THRES, and r_wait_rxbcn_finish = 1 1: update TSFT
  [28:16] BIT_RXBCN_TSFT_THRES rw — used for LPS MAC, if |TSFT - rxbcn.timestamp| > BIT_RXBCN_TSFT_THRES, need to wait fcsok. Else, update TSFT at wmac_rxtsf_rdy (before fcsok) unit is 1us,max is 8ms
  [7] BIT_EN_RXBCN_GT_THRES_CNT rw — enable the counter of BIT_RXBCN_GT_THRES_CNT
  [6] BIT_CLR_RXBCN_GT_THRES_CNT ro — clear the BIT_RXBCN_GT_THRES_CNT to 0
  [5:0] BIT_RXBCN_GT_THRES_CNT ro — valid when BIT_EN_RXBCN_GT_THRES_CNT = 1. counter the number of beacon with the |TSFT - rxbcn.timestamp| exceed the threshold
0x1550 REG_PS_TIMER_D_L
  [31:0] BIT_PS_TIMER_D_L — When the TSF(that select by reg 0x1520 [16:17]) matches the content of this register, the PS_TIMER_D_INT interrupt is issued
0x1554 REG_PS_TIMER_D_H
  [31:0] BIT_PS_TIMER_D_H — When the TSF(that select by reg 0x1520 [16:17]) matches the content of this register, the PS_TIMER_D_INT interrupt is issued
0x1558 REG_PS_TIMER_E_L
  [31:0] BIT_PS_TIMER_E_L — When the TSF (that select by reg 0x1520 [13:12]) matches the content of this register, the PS_TIMER_E_INT interrupt is issued
0x155C REG_PS_TIMER_E_H
  [31:0] BIT_PS_TIMER_E_H — When the TSF (that select by reg 0x1520 [13:12]) matches the content of this register, the PS_TIMER_E_INT interrupt is issued
0x1560 REG_TSFT_HIOE_RFON_L ro
  [31:0] BIT_TSFT_AT_HIOE_RFON_L — when hioe_int_chn_on asserted, latch the tsft[31:0] (select port by 0x1530[0]) 0x1550[[30] BIT_EN_BCNELY_LATCH_TSFT = 1, when bcn_early_int of port0 asserted, latch TSFT
0x1564 REG_TSFT_HIOE_RFON_H ro
  [31:0] BIT_TSFT_AT_HIOE_RFON_H — when hioe_int_chn_on asserted, latch the tsft[63:32] (select port by 0x1530[0]) 0x1550[[30] BIT_EN_BCNELY_LATCH_TSFT = 1, when bcn_early_int of port0 asserted, latch TSFT
0x1568 REG_TSFT_BCN_CCAUP_L ro
  [31:0] BIT_TSFT_AT_BCN_CCA_UP_L — when CCA asserted, latch the tsft[31:0] (select port by 0x1530[0]). updated to this register after judging that it is a beacon frame
0x156C REG_TSFT_BCN_CCAUP_H ro
  [31:0] BIT_TSFT_AT_BCN_CCA_UP_H — when CCA asserted, latch the tsft[63:32] (select port by 0x1530[0]). updated to this register after judging that it is a beacon frame
0x1570 REG_POF_BCNELY_AGG_TBTT reset 0x3
  [24] BIT_EN_P0_TBTT_CNT — enable the tbtt counter function.
  [23:8] BIT_P0_TBTT_CNT_THRS — P0's TBTT counter threshold . Valid when BIT_EN_P0_TBTT_CNT = 1. when tbtt_cnt >= BIT_P0_TBTT_CNT_THRS, assert p0_tbtt_agg_int.
  [7] BIT_EN_POF_ELY_AGG — update bcn_ely_agg initial value of P0 to BIT_INI_POF_ELY_AGG_CNT 1: enable 0: disable
  [6:0] BIT_INI_POF_ELY_AGG_CNT — bcn_ely_agg initial value of P0. Valid when BIT_EN_POF_ELY_AGG = 1
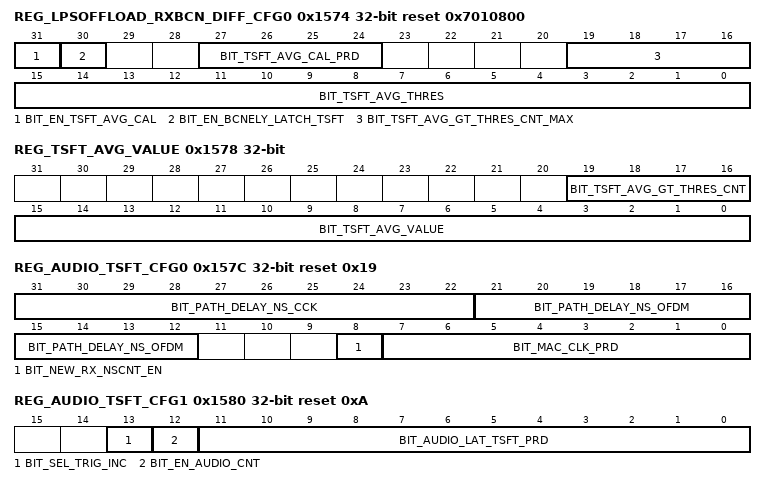
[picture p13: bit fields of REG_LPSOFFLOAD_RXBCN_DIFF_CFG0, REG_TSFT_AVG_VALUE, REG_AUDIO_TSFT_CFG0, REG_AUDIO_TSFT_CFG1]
0x1574 REG_LPSOFFLOAD_RXBCN_DIFF_CFG0 reset 0x7010800
  [31] BIT_EN_TSFT_AVG_CAL — 1: calculate the average value of deltaTSFT(latch hioe_int_chn_on and cca_up) in specified period
  [30] BIT_EN_BCNELY_LATCH_TSFT — 1: latch TSFT to BIT_TSFT_AT_HIOE_RFON (0x153C) when P0's bcn_early int asserted
  [27:24] BIT_TSFT_AVG_CAL_PRD — 2^(BIT_TSFT_AVG_CAL_PERIOD), default is 128 times
  [19:16] BIT_TSFT_AVG_GT_THRES_CNT_MAX — The max times of the BIT_TSFT_AVG_VALUE greater than BIT_TSFT_AVG_THRES, if the BIT_TSFT_AVG_VALUE exceeds the BIT_TSFT_AVG_THRES several times in a row, and the number exceeds the BIT_TSFT_AVG_GT_THRES_CNT_MAX, generate an interrupt
  [15:0] BIT_TSFT_AVG_THRES — The threshold of deltaTSFT(latch hioe_int_chn_on and cca_up), unit us
0x1578 REG_TSFT_AVG_VALUE ro
  [19:16] BIT_TSFT_AVG_GT_THRES_CNT — statistic the times of the BIT_TSFT_AVG_VALUE than BIT_TSFT_AVG_THRES
  [15:0] BIT_TSFT_AVG_VALUE — the average value of deltaTSFT(latch hioe_int_chn_on and cca_up) in specified period
0x157C REG_AUDIO_TSFT_CFG0 reset 0x19
  [31:22] BIT_PATH_DELAY_NS_CCK — the NS part of RX CCK1M PATH DELAY
  [21:12] BIT_PATH_DELAY_NS_OFDM — the NS part of RX OFDM6M PATH DELAY
  [8] BIT_NEW_RX_NSCNT_EN — 1: enable the new ns counter of rx 0: follow old ns counter as tx
  [7:0] BIT_MAC_CLK_PRD — set the period of MAC CLK, default 40M - 25ns
0x1580 REG_AUDIO_TSFT_CFG1 reset 0xA
  [13] BIT_SEL_TRIG_INC — 1: current is TX mode,select P0/P1's tsft for audio tsft sync,according P0/P1's net mode 0: current is RX mode, select P0's beacon timestamp for audio tsft sync
  [12] BIT_EN_AUDIO_CNT — 1: enable counter, count according to BIT_SEL_TRIG_INC
  [11:0] BIT_AUDIO_LAT_TSFT_PRD — indicates the period of rxbcn(P0 rx mode) or TBTT(P1/P0 tx mode), if the counter reaches the BIT_LAT_TSFT_PRD, generate an interrupt
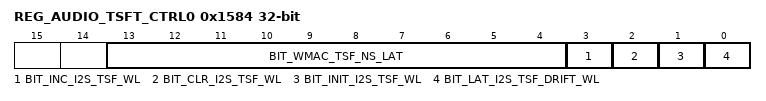
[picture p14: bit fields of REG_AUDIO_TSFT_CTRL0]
0x1584 REG_AUDIO_TSFT_CTRL0 access per field
  [13:4] BIT_WMAC_TSF_NS_LAT ro — wmac_tsf_ns latch value
  [3] BIT_INC_I2S_TSF_WL rw — when set to 1, i2s tsf counter begin to count, when set to 0 i2s tsf counter pause
  [2] BIT_CLR_I2S_TSF_WL ro — when set to 1, clear i2s tsf counter
  [1] BIT_INIT_I2S_TSF_WL ro — set i2s tsf initial value when set to 1, set i2s tsf counter value to r_i2s_tsf_tmp[63:0]
  [0] BIT_LAT_I2S_TSF_DRIFT_WL ro — add/sub drift to i2s tsf counter when set to 1, add/sub r_i2s_tsf_drift[31:0] to i2s tsf counter
0x1588 REG_AUDIO_TSFT_CTRL1
  [31:0] BIT_I2S_TSF_DRIFT — i2s tsf counter drift value
0x158C REG_AUDIO_TSFT_CTRL2
  [31:0] BIT_I2S_TSF_TMP_L — low 32bit of i2s tsf counter initial value
0x1590 REG_AUDIO_TSFT_CTRL3
  [31:0] BIT_I2S_TSF_TMP_H — high 32bit of i2s tsf counter initial value
0x1594 REG_AUDIO_TSFT_LATCH0 ro
  [31:0] BIT_WMAC_TSF_US_LAT_L — low 32bit of wmac_tsf_us latch value
0x1598 REG_AUDIO_TSFT_LATCH1 ro
  [31:0] BIT_WMAC_TSF_US_LAT_H — high 32bit of wmac_tsf_us latch value
0x159C REG_AUDIO_TSFT_LATCH2 ro
  [31:0] BIT_I2S_TSF_LAT_L — low 32bit of i2s_tsf latch value
0x15A0 REG_AUDIO_TSFT_LATCH3 ro
  [31:0] BIT_I2S_TSF_LAT_H — high 32bit of i2s_tsf latch value
